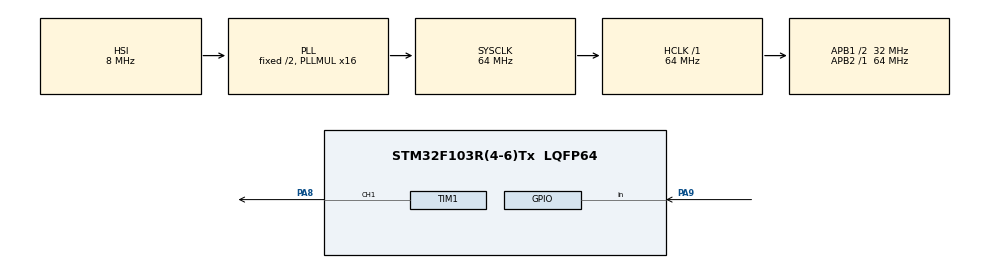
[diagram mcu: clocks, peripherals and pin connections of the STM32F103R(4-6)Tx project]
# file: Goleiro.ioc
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Mcu.Family=STM32F1
Mcu.Name=STM32F103R(4-6)Tx
Mcu.Package=LQFP64
NVIC.PriorityGroup=NVIC_PRIORITYGROUP_4
PA8.Signal=S_TIM1_CH1
PA9.Signal=GPIO_Input
ProjectManager.HeapSize=0x200
ProjectManager.StackSize=0x400
ProjectManager.TargetToolchain=STM32CubeIDE
RCC.AHBFreq_Value=64000000
RCC.APB1CLKDivider=RCC_HCLK_DIV2
RCC.APB1Freq_Value=32000000
RCC.APB1TimFreq_Value=64000000
RCC.APB2Freq_Value=64000000
RCC.APB2TimFreq_Value=64000000
RCC.HCLKFreq_Value=64000000
RCC.PLLMUL=RCC_PLL_MUL16
RCC.SYSCLKFreq_VALUE=64000000
RCC.SYSCLKSource=RCC_SYSCLKSOURCE_PLLCLK
RCC.USBFreq_Value=64000000
SH.S_TIM1_CH1.0=TIM1_CH1,PWM Generation1 CH1
TIM1.Channel-PWM\ Generation1\ CH1=TIM_CHANNEL_1
TIM1.Period=12799
TIM1.Prescaler=9
TIM1.Pulse-PWM\ Generation1\ CH1=0
VP_SYS_VS_ND.Mode=No_Debug
VP_TIM1_VS_ClockSourceINT.Mode=Internal
board=custom

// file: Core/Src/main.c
/* USER CODE BEGIN Header */
/**
  ******************************************************************************
  * @file           : main.c
  * @brief          : Main program body
  ******************************************************************************
  * @attention
  *
  * <h2><center>&copy; Copyright (c) 2021 STMicroelectronics.
  * All rights reserved.</center></h2>
  *
  * This software component is licensed by ST under BSD 3-Clause license,
  * the "License"; You may not use this file except in compliance with the
  * License. You may obtain a copy of the License at:
  *                        opensource.org/licenses/BSD-3-Clause
  *
  ******************************************************************************
  */
/* USER CODE END Header */
#include "main.h"

TIM_HandleTypeDef htim1;

void SystemClock_Config(void);
static void MX_GPIO_Init(void);
static void MX_TIM1_Init(void);

int main(void)
{

  /* MCU Configuration--------------------------------------------------------*/

  /* Reset of all peripherals, Initializes the Flash interface and the Systick. */
  HAL_Init();

  /* Configure the system clock */
  SystemClock_Config();

  /* Initialize all configured peripherals */
  MX_GPIO_Init();
  MX_TIM1_Init();
  /* USER CODE BEGIN 2 */
  HAL_TIM_PWM_Start(&htim1, TIM_CHANNEL_1);
  /* USER CODE END 2 */

  /* Infinite loop */
  /* USER CODE BEGIN WHILE */
  while (1)
  {

	  if(HAL_GPIO_ReadPin(GPIOA,GPIO_PIN_9)==GPIO_PIN_RESET)
	  	  		  {
	  	  			  htim1.Instance->CCR1 = 1;  // chave aberta
	  	  		  }
	  	  		  else
	  	  		  {
	  	  			  htim1.Instance->CCR1 = 3199;  // chave fechada
	  	  		  }
	  /*

	  	 * 8Mhz				64Mhz					64Mhz = 64.000.000
	  	 * 1 = 90			1 = 90					64M/Cp = 500 						Cp = Counter Period
	  	 * 2000 = 45		1600 = 45				Valor maximo para Cp = 65 535
	  	 * 4000 = 0			3200 = 0				128000 > 65535
	  	 * 6000 = -45		4800 = -45				128000 / Prescalar = x
	  	 * 8000 = -90		6400 = -90				x < 65535
	  	 *											Val finais:
	  	 *Cp = 16000-1	     						Cp = 128 000 - 1
	  	 *Prescaler = 0 							Prescaler = 10 - 1
	  	 */

	  /*
	   * 	  	HAL_UART_Transmit(&huart1,char2,10,100);
		HAL_UART_Receive(&huart1, rx_buffer,2,100);	//Recebe uma msg
		uart_rd = rx_buffer[0];
		switch(uart_rd)
		{
		case 'n':
			htim1.Instance->CCR1 = 3200;
			break;
		case 'o':
			htim1.Instance->CCR1 = 6400;
			break;
		}
	   */

    /* USER CODE END WHILE */

  }
}

void SystemClock_Config(void)
{
  RCC_OscInitTypeDef RCC_OscInitStruct = {0};
  RCC_ClkInitTypeDef RCC_ClkInitStruct = {0};

  /** Initializes the RCC Oscillators according to the specified parameters
  * in the RCC_OscInitTypeDef structure.
  */
  RCC_OscInitStruct.OscillatorType = RCC_OSCILLATORTYPE_HSI;
  RCC_OscInitStruct.HSIState = RCC_HSI_ON;
  RCC_OscInitStruct.HSICalibrationValue = RCC_HSICALIBRATION_DEFAULT;
  RCC_OscInitStruct.PLL.PLLState = RCC_PLL_ON;
  RCC_OscInitStruct.PLL.PLLSource = RCC_PLLSOURCE_HSI_DIV2;
  RCC_OscInitStruct.PLL.PLLMUL = RCC_PLL_MUL16;
  if (HAL_RCC_OscConfig(&RCC_OscInitStruct) != HAL_OK)
  {
    Error_Handler();
  }
  /** Initializes the CPU, AHB and APB buses clocks
  */
  RCC_ClkInitStruct.ClockType = RCC_CLOCKTYPE_HCLK|RCC_CLOCKTYPE_SYSCLK
                              |RCC_CLOCKTYPE_PCLK1|RCC_CLOCKTYPE_PCLK2;
  RCC_ClkInitStruct.SYSCLKSource = RCC_SYSCLKSOURCE_PLLCLK;
  RCC_ClkInitStruct.AHBCLKDivider = RCC_SYSCLK_DIV1;
  RCC_ClkInitStruct.APB1CLKDivider = RCC_HCLK_DIV2;
  RCC_ClkInitStruct.APB2CLKDivider = RCC_HCLK_DIV1;

  if (HAL_RCC_ClockConfig(&RCC_ClkInitStruct, FLASH_LATENCY_2) != HAL_OK)
  {
    Error_Handler();
  }
}

static void MX_TIM1_Init(void)
{

  TIM_ClockConfigTypeDef sClockSourceConfig = {0};
  TIM_MasterConfigTypeDef sMasterConfig = {0};
  TIM_OC_InitTypeDef sConfigOC = {0};
  TIM_BreakDeadTimeConfigTypeDef sBreakDeadTimeConfig = {0};

  htim1.Instance = TIM1;
  htim1.Init.Prescaler = 9;
  htim1.Init.CounterMode = TIM_COUNTERMODE_UP;
  htim1.Init.Period = 12799;
  htim1.Init.ClockDivision = TIM_CLOCKDIVISION_DIV1;
  htim1.Init.RepetitionCounter = 0;
  htim1.Init.AutoReloadPreload = TIM_AUTORELOAD_PRELOAD_DISABLE;
  if (HAL_TIM_Base_Init(&htim1) != HAL_OK)
  {
    Error_Handler();
  }
  sClockSourceConfig.ClockSource = TIM_CLOCKSOURCE_INTERNAL;
  if (HAL_TIM_ConfigClockSource(&htim1, &sClockSourceConfig) != HAL_OK)
  {
    Error_Handler();
  }
  if (HAL_TIM_PWM_Init(&htim1) != HAL_OK)
  {
    Error_Handler();
  }
  sMasterConfig.MasterOutputTrigger = TIM_TRGO_RESET;
  sMasterConfig.MasterSlaveMode = TIM_MASTERSLAVEMODE_DISABLE;
  if (HAL_TIMEx_MasterConfigSynchronization(&htim1, &sMasterConfig) != HAL_OK)
  {
    Error_Handler();
  }
  sConfigOC.OCMode = TIM_OCMODE_PWM1;
  sConfigOC.Pulse = 0;
  sConfigOC.OCPolarity = TIM_OCPOLARITY_HIGH;
  sConfigOC.OCNPolarity = TIM_OCNPOLARITY_HIGH;
  sConfigOC.OCFastMode = TIM_OCFAST_DISABLE;
  sConfigOC.OCIdleState = TIM_OCIDLESTATE_RESET;
  sConfigOC.OCNIdleState = TIM_OCNIDLESTATE_RESET;
  if (HAL_TIM_PWM_ConfigChannel(&htim1, &sConfigOC, TIM_CHANNEL_1) != HAL_OK)
  {
    Error_Handler();
  }
  sBreakDeadTimeConfig.OffStateRunMode = TIM_OSSR_DISABLE;
  sBreakDeadTimeConfig.OffStateIDLEMode = TIM_OSSI_DISABLE;
  sBreakDeadTimeConfig.LockLevel = TIM_LOCKLEVEL_OFF;
  sBreakDeadTimeConfig.DeadTime = 0;
  sBreakDeadTimeConfig.BreakState = TIM_BREAK_DISABLE;
  sBreakDeadTimeConfig.BreakPolarity = TIM_BREAKPOLARITY_HIGH;
  sBreakDeadTimeConfig.AutomaticOutput = TIM_AUTOMATICOUTPUT_DISABLE;
  if (HAL_TIMEx_ConfigBreakDeadTime(&htim1, &sBreakDeadTimeConfig) != HAL_OK)
  {
    Error_Handler();
  }
  HAL_TIM_MspPostInit(&htim1);

}

static void MX_GPIO_Init(void)
{
  GPIO_InitTypeDef GPIO_InitStruct = {0};

  /* GPIO Ports Clock Enable */
  __HAL_RCC_GPIOA_CLK_ENABLE();

  /*Configure GPIO pin : PA9 */
  GPIO_InitStruct.Pin = GPIO_PIN_9;
  GPIO_InitStruct.Mode = GPIO_MODE_INPUT;
  GPIO_InitStruct.Pull = GPIO_NOPULL;
  HAL_GPIO_Init(GPIOA, &GPIO_InitStruct);

}

void Error_Handler(void)
{
  __disable_irq();
  while (1)
  {
  }
}

/************************ (C) COPYRIGHT STMicroelectronics *****END OF FILE****/
